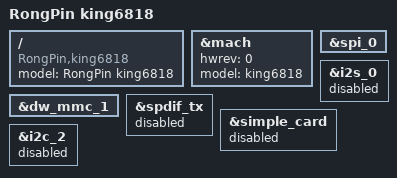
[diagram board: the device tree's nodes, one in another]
/*
 * (C) Copyright 2017 FriendlyElec Computer Tech. Co., Ltd.
 * (http://www.friendlyarm.com)
 *
 * This program is free software; you can redistribute it and/or
 * modify it under the terms of the GNU General Public License
 * as published by the Free Software Foundation; either version 2
 * of the License, or (at your option) any later version.
 *
 * This program is distributed in the hope that it will be useful,
 * but WITHOUT ANY WARRANTY; without even the implied warranty of
 * MERCHANTABILITY or FITNESS FOR A PARTICULAR PURPOSE.  See the
 * GNU General Public License for more details.
 *
 * You should have received a copy of the GNU General Public License
 * along with this program.  If not, see <http://www.gnu.org/licenses/>.
 */

/dts-v1/;
#include "s5p6818-king6818-common.dtsi"

/ {
	model = "RongPin king6818";
	compatible = "RongPin,king6818", "nexell,s5p6818";
};

&mach {
	hwrev = <0>;
	model = "king6818";
};

&dw_mmc_1 {
	status = "okay";
};

&spi_0 {
	/delete-node/ fbtft@0;
};
/* 1. 彻底禁用音频相关，防止 Oops 崩溃 */
&i2s_0 { status = "disabled"; };
&spdif_tx { status = "disabled"; };
&simple_card { status = "disabled"; };

/* 2. 禁用所有触摸屏，释放 GPIO 15/16 给 I2C 总线使用 */
&i2c_2 {
    status = "disabled"; 
};
